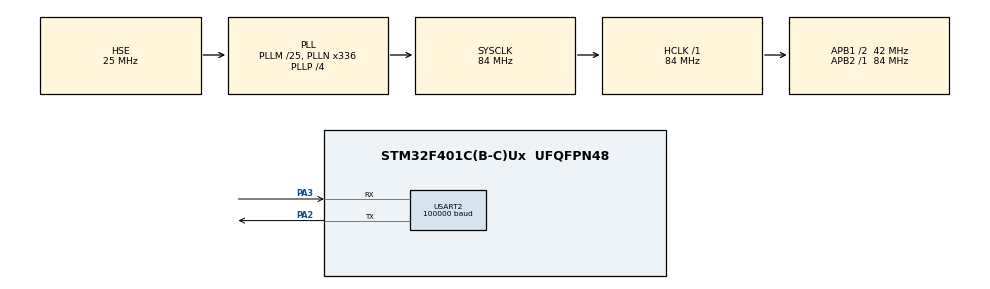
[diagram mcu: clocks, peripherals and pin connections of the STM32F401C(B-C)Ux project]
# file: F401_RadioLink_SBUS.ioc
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Dma.Request0=USART2_RX
Dma.USART2_RX.0.Direction=DMA_PERIPH_TO_MEMORY
Dma.USART2_RX.0.FIFOMode=DMA_FIFOMODE_DISABLE
Dma.USART2_RX.0.Instance=DMA1_Stream5
Dma.USART2_RX.0.MemDataAlignment=DMA_MDATAALIGN_BYTE
Dma.USART2_RX.0.MemInc=DMA_MINC_ENABLE
Dma.USART2_RX.0.Mode=DMA_CIRCULAR
Dma.USART2_RX.0.PeriphDataAlignment=DMA_PDATAALIGN_BYTE
Dma.USART2_RX.0.PeriphInc=DMA_PINC_DISABLE
Dma.USART2_RX.0.Priority=DMA_PRIORITY_LOW
Mcu.Family=STM32F4
Mcu.Name=STM32F401C(B-C)Ux
Mcu.Package=UFQFPN48
NVIC.DMA1_Stream5_IRQn=true\:0\:0\:false\:false\:true\:false\:true
NVIC.PriorityGroup=NVIC_PRIORITYGROUP_4
PA13.Mode=Trace_Asynchronous_SW
PA13.Signal=SYS_JTMS-SWDIO
PA14.Mode=Trace_Asynchronous_SW
PA14.Signal=SYS_JTCK-SWCLK
PA2.Mode=Asynchronous
PA2.Signal=USART2_TX
PA3.Mode=Asynchronous
PA3.Signal=USART2_RX
PB3.Mode=Trace_Asynchronous_SW
PB3.Signal=SYS_JTDO-SWO
PH0\ -\ OSC_IN.Mode=HSE-External-Oscillator
PH0\ -\ OSC_IN.Signal=RCC_OSC_IN
PH1\ -\ OSC_OUT.Mode=HSE-External-Oscillator
PH1\ -\ OSC_OUT.Signal=RCC_OSC_OUT
ProjectManager.HeapSize=0x200
ProjectManager.StackSize=0x400
ProjectManager.TargetToolchain=STM32CubeIDE
RCC.48MHZClocksFreq_Value=48000000
RCC.AHBFreq_Value=84000000
RCC.APB1CLKDivider=RCC_HCLK_DIV2
RCC.APB1Freq_Value=42000000
RCC.APB1TimFreq_Value=84000000
RCC.APB2Freq_Value=84000000
RCC.APB2TimFreq_Value=84000000
RCC.CortexFreq_Value=84000000
RCC.HCLKFreq_Value=84000000
RCC.HSE_VALUE=25000000
RCC.HSI_VALUE=16000000
RCC.LSE_VALUE=32768
RCC.PLLM=25
RCC.PLLN=336
RCC.PLLP=RCC_PLLP_DIV4
RCC.PLLQ=7
RCC.PLLSourceVirtual=RCC_PLLSOURCE_HSE
RCC.SYSCLKFreq_VALUE=84000000
RCC.SYSCLKSource=RCC_SYSCLKSOURCE_PLLCLK
RCC.VCOOutputFreq_Value=336000000
USART2.BaudRate=100000
USART2.Mode=MODE_RX
USART2.Parity=PARITY_EVEN
USART2.StopBits=STOPBITS_2
USART2.VirtualMode=VM_ASYNC
board=custom

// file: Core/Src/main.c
/* USER CODE BEGIN Header */
/**
 ******************************************************************************
 * @file           : main.c
 * @brief          : Main program body
 ******************************************************************************
 * @attention
 *
 * <h2><center>&copy; Copyright (c) 2021 STMicroelectronics.
 * All rights reserved.</center></h2>
 *
 * This software component is licensed by ST under BSD 3-Clause license,
 * the "License"; You may not use this file except in compliance with the
 * License. You may obtain a copy of the License at:
 *                        opensource.org/licenses/BSD-3-Clause
 *
 ******************************************************************************
 */
/* USER CODE END Header */
#include "main.h"
#include "dma.h"
#include "usart.h"
#include "gpio.h"

/* USER CODE BEGIN Includes */
#include <string.h>
#include <stdbool.h>
/* USER CODE END Includes */

/* USER CODE BEGIN PTD */
#define SBUS_SIGNAL_OK          0x00
#define SBUS_SIGNAL_LOST        0x01
#define SBUS_SIGNAL_FAILSAFE    0x03
/* USER CODE END PTD */

void SystemClock_Config(void);

/* USER CODE BEGIN 0 */
uint16_t failsafe_status;
uint16_t SBUS_footer;
uint8_t buf[25];
uint16_t CH[18];

uint8_t pre_catch_buf[1];
int pre_init_counter = 0;
bool start_counting = false;
bool catch_signal = false;

void HAL_UART_RxCpltCallback(UART_HandleTypeDef *huart)
{
	if (pre_catch_buf[0] == 0x0F) start_counting = true;

	if (pre_init_counter < 24 && start_counting == true)
		{
			pre_init_counter++;
			return;
		}
	else if (catch_signal == false)
		{
			catch_signal = true;
			HAL_UART_AbortReceive(&huart2);
			HAL_UART_Receive_DMA(&huart2, buf, 25);
			return;
		}

	if (buf[0] == 0x0F)
		{
			CH[0] = (buf[1] >> 0 | (buf[2] << 8)) & 0x07FF;
			CH[1] = (buf[2] >> 3 | (buf[3] << 5)) & 0x07FF;
			CH[2] = (buf[3] >> 6 | (buf[4] << 2) | buf[5] << 10) & 0x07FF;
			CH[3] = (buf[5] >> 1 | (buf[6] << 7)) & 0x07FF;
			CH[4] = (buf[6] >> 4 | (buf[7] << 4)) & 0x07FF;
			CH[5] = (buf[7] >> 7 | (buf[8] << 1) | buf[9] << 9) & 0x07FF;
			CH[6] = (buf[9] >> 2 | (buf[10] << 6)) & 0x07FF;
			CH[7] = (buf[10] >> 5 | (buf[11] << 3)) & 0x07FF;
			CH[8] = (buf[12] << 0 | (buf[13] << 8)) & 0x07FF;
			CH[9] = (buf[13] >> 3 | (buf[14] << 5)) & 0x07FF;
			CH[10] = (buf[14] >> 6 | (buf[15] << 2) | buf[16] << 10) & 0x07FF;
			CH[11] = (buf[16] >> 1 | (buf[17] << 7)) & 0x07FF;
			CH[12] = (buf[17] >> 4 | (buf[18] << 4)) & 0x07FF;
			CH[13] = (buf[18] >> 7 | (buf[19] << 1) | buf[20] << 9) & 0x07FF;
			CH[14] = (buf[20] >> 2 | (buf[21] << 6)) & 0x07FF;
			CH[15] = (buf[21] >> 5 | (buf[22] << 3)) & 0x07FF;

			if (buf[23] & (1 << 0))
				{
					CH[16] = 1;
				}
			else
				{
					CH[16] = 0;
				}

			if (buf[23] & (1 << 1))
				{
					CH[17] = 1;
				}
			else
				{
					CH[17] = 0;
				}

			// Failsafe
			failsafe_status = SBUS_SIGNAL_OK;
			if (buf[23] & (1 << 2))
				{
					failsafe_status = SBUS_SIGNAL_LOST;
				}

			if (buf[23] & (1 << 3))
				{
					failsafe_status = SBUS_SIGNAL_FAILSAFE;
				}

			SBUS_footer = buf[24];

		}
	else
		{
			catch_signal = false;
			start_counting = false;
			catch_signal = false;
			pre_init_counter = 0;
			HAL_UART_AbortReceive(&huart2);
			HAL_UART_Receive_DMA(&huart2, pre_catch_buf, 1);
			return;
		}
}
/* USER CODE END 0 */

int main(void)
{

  /* MCU Configuration--------------------------------------------------------*/

  /* Reset of all peripherals, Initializes the Flash interface and the Systick. */
  HAL_Init();

  /* Configure the system clock */
  SystemClock_Config();

  /* Initialize all configured peripherals */
  MX_GPIO_Init();
  MX_DMA_Init();
  MX_USART2_UART_Init();
  /* USER CODE BEGIN 2 */
  HAL_UART_Receive_DMA(&huart2, pre_catch_buf, 1);
  /* USER CODE END 2 */

  /* Infinite loop */
	while (1)
	{

	}
}

void SystemClock_Config(void)
{
  RCC_OscInitTypeDef RCC_OscInitStruct = {0};
  RCC_ClkInitTypeDef RCC_ClkInitStruct = {0};

  /** Configure the main internal regulator output voltage
  */
  __HAL_RCC_PWR_CLK_ENABLE();
  __HAL_PWR_VOLTAGESCALING_CONFIG(PWR_REGULATOR_VOLTAGE_SCALE2);
  /** Initializes the RCC Oscillators according to the specified parameters
  * in the RCC_OscInitTypeDef structure.
  */
  RCC_OscInitStruct.OscillatorType = RCC_OSCILLATORTYPE_HSE;
  RCC_OscInitStruct.HSEState = RCC_HSE_ON;
  RCC_OscInitStruct.PLL.PLLState = RCC_PLL_ON;
  RCC_OscInitStruct.PLL.PLLSource = RCC_PLLSOURCE_HSE;
  RCC_OscInitStruct.PLL.PLLM = 25;
  RCC_OscInitStruct.PLL.PLLN = 336;
  RCC_OscInitStruct.PLL.PLLP = RCC_PLLP_DIV4;
  RCC_OscInitStruct.PLL.PLLQ = 7;
  if (HAL_RCC_OscConfig(&RCC_OscInitStruct) != HAL_OK)
  {
    Error_Handler();
  }
  /** Initializes the CPU, AHB and APB buses clocks
  */
  RCC_ClkInitStruct.ClockType = RCC_CLOCKTYPE_HCLK|RCC_CLOCKTYPE_SYSCLK
                              |RCC_CLOCKTYPE_PCLK1|RCC_CLOCKTYPE_PCLK2;
  RCC_ClkInitStruct.SYSCLKSource = RCC_SYSCLKSOURCE_PLLCLK;
  RCC_ClkInitStruct.AHBCLKDivider = RCC_SYSCLK_DIV1;
  RCC_ClkInitStruct.APB1CLKDivider = RCC_HCLK_DIV2;
  RCC_ClkInitStruct.APB2CLKDivider = RCC_HCLK_DIV1;

  if (HAL_RCC_ClockConfig(&RCC_ClkInitStruct, FLASH_LATENCY_2) != HAL_OK)
  {
    Error_Handler();
  }
}

void Error_Handler(void)
{
	__disable_irq();
	while (1) {
	}
}

/************************ (C) COPYRIGHT STMicroelectronics *****END OF FILE****/
